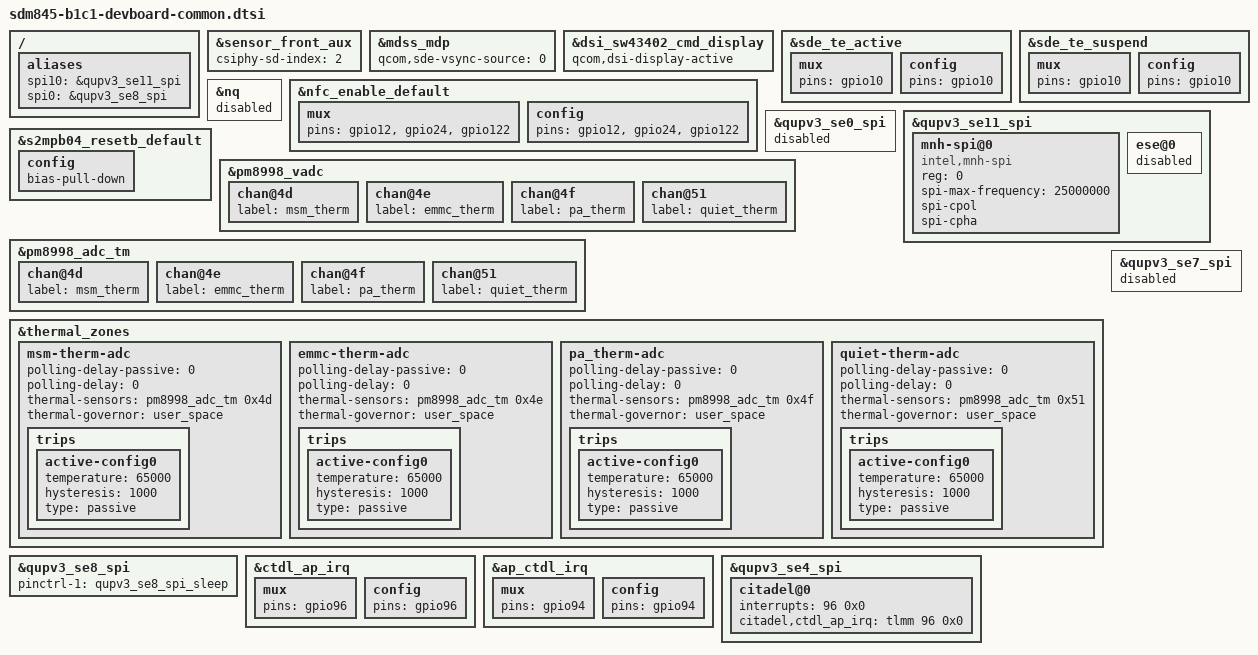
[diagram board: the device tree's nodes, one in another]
/* Copyright (c) 2016, The Linux Foundation. All rights reserved.
 *
 * This program is free software; you can redistribute it and/or modify
 * it under the terms of the GNU General Public License version 2 and
 * only version 2 as published by the Free Software Foundation.
 *
 * This program is distributed in the hope that it will be useful,
 * but WITHOUT ANY WARRANTY; without even the implied warranty of
 * MERCHANTABILITY or FITNESS FOR A PARTICULAR PURPOSE.  See the
 * GNU General Public License for more details.
 */

#include "sdm845-b1c1-common.dtsi"

#include "sdm845-taimen-touch-stm-ftm4.dtsi"
#include "sdm845-b1c1-devboard-audio.dtsi"
#include "sdm845-b1c1-devboard-wcharger.dtsi"

&sensor_front_aux {
	csiphy-sd-index = <2>;
};

&mdss_mdp {
	qcom,sde-vsync-source = <0>;
};

&dsi_sw43402_cmd_display {
	qcom,dsi-display-active;
};

&sde_te_active {
	mux {
		pins = "gpio10";
	};
	config {
		pins = "gpio10";
	};
};

&sde_te_suspend {
	mux {
		pins = "gpio10";
	};
	config {
		pins = "gpio10";
	};
};

&nq {
	status = "disabled";
};

&nfc_enable_default {
	mux {
		/* 12: NFC ENABLE, 24:ESE Enable, 122:ESE WAKEUP INT */
		pins = "gpio12", "gpio24", "gpio122";
	};
	config {
		pins = "gpio12", "gpio24", "gpio122";
	};
};

/* B1 P1 has easel spi connected to se11 */
/ {
	aliases {
		spi10 = &qupv3_se11_spi;
	};
};
&qupv3_se0_spi {
	status = "disabled";
};
&qupv3_se11_spi {
	status = "okay";
	mnh-spi@0 {
		compatible = "intel,mnh-spi";
		reg = <0>;
		spi-max-frequency = <25000000>;
		spi-cpol;
		spi-cpha;
	};
	ese@0 {
		status = "disabled";
	};
};

/* devboard doesn't have easel PMIC, so we need a pull-down on resetb */
&s2mpb04_resetb_default {
	config {
		/delete-property/ bias-disable;
		bias-pull-down;
	};
};

/* override thermistors config for devborad only */
&pm8998_vadc {
	chan@4d {
		label = "msm_therm";
	};

	chan@4e {
		label = "emmc_therm";
	};

	chan@4f {
		label = "pa_therm";
	};

	chan@51 {
		label = "quiet_therm";
	};
};

&pm8998_adc_tm {
	chan@4d {
		label = "msm_therm";
	};

	chan@4e {
		label = "emmc_therm";
	};

	chan@4f {
		label = "pa_therm";
	};

	chan@51 {
		label = "quiet_therm";
	};
};

&thermal_zones {
	/delete-node/sdm-therm-adc;
	/delete-node/usbc-therm-adc;
	/delete-node/pmi_therm-adc;

	msm-therm-adc {
		polling-delay-passive = <0>;
		polling-delay = <0>;
		thermal-sensors = <&pm8998_adc_tm 0x4d>;
		thermal-governor = "user_space";

		trips {
			active-config0 {
				temperature = <65000>;
				hysteresis = <1000>;
				type = "passive";
			};
		};
	};

	emmc-therm-adc {
		polling-delay-passive = <0>;
		polling-delay = <0>;
		thermal-sensors = <&pm8998_adc_tm 0x4e>;
		thermal-governor = "user_space";

		trips {
			active-config0 {
				temperature = <65000>;
				hysteresis = <1000>;
				type = "passive";
			};
		};
	};

	pa_therm-adc {
		polling-delay-passive = <0>;
		polling-delay = <0>;
		thermal-sensors = <&pm8998_adc_tm 0x4f>;
		thermal-governor = "user_space";

		trips {
			active-config0 {
				temperature = <65000>;
				hysteresis = <1000>;
				type = "passive";
			};
		};
	};

	quiet-therm-adc {
		polling-delay-passive = <0>;
		polling-delay = <0>;
		thermal-sensors = <&pm8998_adc_tm 0x51>;
		thermal-governor = "user_space";

		trips {
			active-config0 {
				temperature = <65000>;
				hysteresis = <1000>;
				type = "passive";
			};
		};
	};
};

&qupv3_se7_spi {
	status = "disable";
};

&qupv3_se8_spi {
	status = "ok";
	/* Sleep the SPI lines when not in use. This allows SLPI to share the
	 * bus with the AP. */
	pinctrl-1 = <&qupv3_se8_spi_sleep>;
};

/ {
	aliases {
		spi0 = &qupv3_se8_spi;
	};
};

&ctdl_ap_irq {
	mux {
		pins = "gpio96";
	};

	config {
		pins = "gpio96";
	};
};

&ap_ctdl_irq {
	mux {
		pins = "gpio94";
	};

	config {
		pins = "gpio94";
	};
};

&qupv3_se4_spi {
	citadel@0 {
		interrupts = <96 0x0>;
		citadel,ctdl_ap_irq = <&tlmm 96 0x0>;
	};
};
